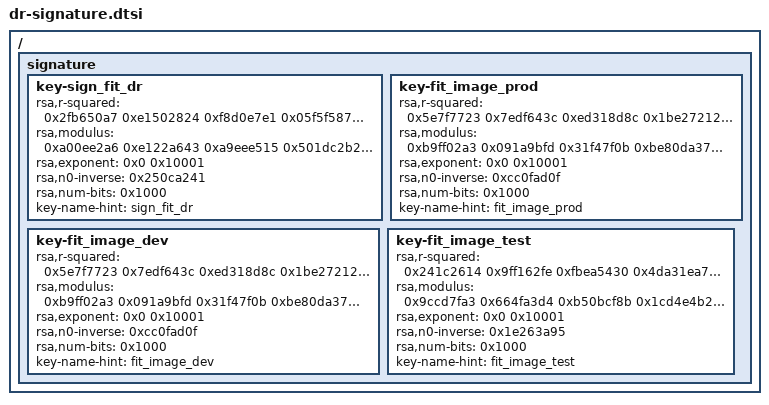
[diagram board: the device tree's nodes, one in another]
/ {
	signature {

		key-sign_fit_dr {
			rsa,r-squared = <
				0x2fb650a7 0xe1502824 0xf8d0e7e1 0x05f5f587
				0xeb7a8b7b 0x9eb11322 0xbd7e9bcb 0x8206080f
				0x1e3cef59 0xcbdcf8fe 0x8d390c50 0x8037e907
				0x23c142a7 0x543cceb7 0x621bd0e6 0x40295e5f
				0x391752dc 0x218a99db 0xe4e37117 0x1306a107
				0x48409d4e 0xf80b34be 0x4c174da6 0x78f461b9
				0xd5cb24da 0x44b6b164 0x1b209ac6 0xd7333065
				0xe70ed5af 0x31e8fc6b 0x88b9d6f3 0x11a98321
				0x17a40d6b 0xe5fcba2b 0x6326f2e3 0x79c96d24
				0x60183420 0xe6ca6753 0x1314e6e8 0xf78f9bad
				0xf9584ec3 0x8d96b01a 0xd9dd74f8 0xb382ae35
				0x01f6a1ef 0xf0c2f379 0x0aa90f7c 0xfae0b0cb
				0x009eaa74 0xa32082ee 0xbd0abb01 0x92b7ecca
				0xcaa34dc5 0xc3ba530f 0x292755a8 0x004a4f96
				0x81c959b3 0x697cb131 0xfade8068 0xeed65604
				0xcbabe22d 0x4c5c093d 0xfacc3274 0x638f702e
				0x1f32caa0 0x23070771 0xaa4fb380 0x864e15f1
				0x963bd9d5 0x59dc21a5 0xd2d697c0 0xe0d09aed
				0x384b783b 0x9a5ba691 0x451a8d71 0x527e2852
				0x044bebe8 0x35c86a40 0x13f5a72b 0x7377f698
				0xefaf8fc3 0x18c6d440 0x7d257bfa 0xb29f66de
				0xa95f6079 0x5b55c139 0x1c2a168a 0x553f8544
				0x6c0fc641 0x30a914b1 0xc3c75446 0x1aaf9767
				0x19353101 0xdaf74e9b 0xab11b880 0x2d505a41
				0xe6ab1942 0xdb8592e8 0xea2b1317 0xdabceab7
				0x2d5bd5dc 0x5b2d1a1b 0x47bb324f 0x76ce07c4
				0xb0584434 0xcea93d41 0xb47369fc 0x6bda6210
				0x47a1fa15 0x17a2eaad 0x804510fd 0x710039de
				0x123fba1a 0xc02a9ba6 0xc5431eba 0xa96c2a70
				0x09beacbe 0x89b1bf60 0x5a650585 0x33fd26ca
				0x9bf031a4 0x23501331 0x43520b8d 0x8d8d7ec7
				0x51b2d9a4 0x05c2f2e8 0x9d800997 0xadcf95dd>;
			rsa,modulus= <
				0xa00ee2a6 0xe122a643 0xa9eee515 0x501dc2b2
				0x8f87f49b 0x566f039c 0x6ca342ff 0xdfe728c8
				0x5d0c82f9 0xaa106b88 0xc51a33b4 0x5aea1a0b
				0xf780bc2f 0xf09a7ae7 0xdb86575c 0x652f8f2b
				0x6c101755 0x1bb0c52b 0x005ab815 0x106d1b86
				0xd66664f4 0x87d39dac 0x89ed97ae 0xfb83fa53
				0x511d619e 0x1c3f01d5 0x858c266b 0xd2375fa9
				0x09c2f104 0x677b7182 0x45ddfc13 0x7c301188
				0x5ef2b94a 0x991a366b 0x1047d3fb 0x90499069
				0x3e91c15e 0x0897c597 0x30933df0 0x60fe302b
				0xaf395dca 0xbe724033 0x81157f75 0x707f5711
				0x793b7b2a 0x20abeba5 0x80fe7464 0x017028ac
				0x15a0745b 0x699a4220 0xbab8455d 0x136c8bbc
				0xbb8e1f8e 0xa4ffa878 0x1f366be0 0x80975e46
				0x67200689 0x503ef476 0x0be48772 0xce8e77ba
				0x4fd15916 0x884b39ea 0x1b784e04 0x8254f573
				0x42288801 0x393ba201 0xe6aaede2 0xcf62348b
				0x6bf3d6dd 0xeda56748 0x0d336017 0x80448b4e
				0x1e83f05c 0x7484a4d9 0x5f9dda54 0x0742f0f3
				0xedd00d16 0x9d09a67d 0x0f41d03b 0x9a09c160
				0xe2c45df0 0x5cb8b441 0x7d954e50 0x744d3a75
				0x7eae8f1a 0x4ce7b501 0x519b1e55 0x666fbfaf
				0x81e31ba1 0x0a7757bf 0x7b38c350 0x459175c4
				0x4848fef4 0x372e631c 0x0d922ae3 0x987b57be
				0x1a81a596 0x7a16dbae 0x52f839f8 0x3696d8eb
				0xd8810d9f 0x4d36db32 0x2be18174 0x5087b886
				0xc74ab6ad 0x2fe797cd 0x4f760b48 0x7653d92a
				0x3c50c45c 0x4b5921ce 0xef45d786 0x6fa53475
				0x3adaef9f 0x226e0f40 0x36fe1c5d 0xe47e021b
				0x826a2ba3 0xa2e30394 0x6c58b319 0x1002f051
				0x62a1a22a 0x29d97516 0x2af0ab82 0x06fe8223
				0xa7e085f5 0x76b9f9dc 0x9b242b3c 0x709b923f>;
			rsa,exponent = <0x0 0x10001>;
			rsa,n0-inverse = <0x250ca241>;
			rsa,num-bits = <0x1000>;
			key-name-hint = "sign_fit_dr";
		};

		key-fit_image_prod {
			rsa,r-squared = <
				0x5e7f7723 0x7edf643c 0xed318d8c 0x1be27212
				0x87641605 0x99bf037b 0xbbb2278b 0x48a3ab02
				0xbbbebda8 0xbc994abd 0x35f1f0e1 0xeb78b2e1
				0xfd072532 0x99a55eac 0x50be9aef 0xf11b851c
				0x0294a416 0x81ec1588 0xcace2984 0xd508afe3
				0x8f89d704 0x1e74e7df 0x12f9cd6f 0x2916cb16
				0xb9531ba1 0x9f27f594 0x2e4b36fa 0xba67bce0
				0x696ca8a9 0x73f5885e 0x1542c50e 0x50430568
				0xead3d1c3 0x1589bff5 0xbf9a94a7 0xf0a8f86a
				0x1e82deb6 0xc0ba71f3 0x7791eac0 0x8c42e734
				0xdd7285b3 0x9666fe51 0x926850e5 0x3ea37424
				0x72ebab59 0x7e66f9c1 0x23f030b6 0x70c079f7
				0x74a72549 0x16230ba9 0x8d69cf98 0x191c7c44
				0xb28715f7 0x580bb377 0x977fabcc 0xf6d44408
				0x5194f852 0x2cc58ab9 0xda395064 0x7ce8d213
				0xe7931e51 0x5a73dd68 0xdbb619c6 0x31709c8b
				0x176126ee 0x408469a8 0x27d16301 0x36d61dfc
				0x5e16a862 0x26cb8019 0x3f2204d9 0x13726397
				0x670e83ba 0x29c6a6eb 0x9c0d1436 0x235adec0
				0x365875ad 0xc5e6d473 0x02e92297 0x2833cda9
				0x3efea6c0 0x8b06fd7c 0x9d2e4e84 0xe64ee466
				0x735e2984 0x89090d3c 0x271bcf65 0x7ab1a58e
				0x96899b34 0x9a15d437 0x590b8b47 0xfc0d41fb
				0x889bcf9e 0x9fb11dad 0x61c32e2c 0x55126e7e
				0x492ff152 0xe74437f9 0x830685d3 0x037e5f31
				0x985a7a69 0x228de426 0x47720340 0x55697744
				0x90a6e2d7 0x65169746 0xa3e04e9c 0x6a592eb2
				0xa5c03426 0xec1f1dff 0x3dc86537 0xeb32b971
				0x73939bfa 0x1c45b14e 0x3bd2e8ca 0x3b48d638
				0xb11e65b3 0xa2716628 0x0019a273 0xb74ed9d2
				0xaec9f007 0xfe2ac7ce 0x6f25dda9 0xd989fe5d
				0x7b339440 0xaaccbd71 0xfe5bbbf6 0x21ca9f7d>;
			rsa,modulus= <
				0xb9ff02a3 0x091a9bfd 0x31f47f0b 0xbe80da37
				0x8c33ba51 0x2ff67e8c 0x239575d3 0x855c9eb2
				0x6b491d9f 0xabf75f1e 0xd673483b 0xfe334de7
				0x2aecd022 0x41c0fc0a 0xb0bc0587 0xe2b6349e
				0xbba1a138 0xedddb33b 0x186843bf 0x6b3ea699
				0x4ea4dcff 0x0d01ee09 0x112a2dd3 0xac1644b7
				0xf9f9cdd6 0x8bf863fc 0x5b4e659c 0x53f2162c
				0x03713f88 0xedfbdd0b 0x08e72807 0xfd57155f
				0x6b7209bd 0xbe439fd3 0xbf2babb3 0xf440853d
				0x867e56a0 0xa8d2d967 0xe1327a2b 0x4b0705b3
				0x29179650 0x4d5aa9a8 0x845197dc 0xbaabfa41
				0xcac85cc7 0xaedf064f 0xa8942873 0xad766abb
				0xcc659b0c 0x165eaae0 0x735aa0a3 0x5f799797
				0x6b12220b 0xeeb018c1 0x45055bb7 0xdd7462a4
				0xa765db3b 0x62a1aae4 0x00ba9644 0xae22f488
				0x8dd9d7dc 0x6e80d659 0xe49aedbe 0xfd0212ee
				0xc8180670 0x92494b84 0xab32ef8b 0xf3ed4fb3
				0x9f8dcca1 0x6d243497 0x11ec86e6 0x8dc485bc
				0x547ca485 0x4a20f1f6 0xf490293d 0x81aaf7a7
				0x53e3bdde 0x9c10512d 0x4693e06f 0xf4010d2a
				0x653673d2 0x2dc81307 0xddfa74cd 0xd2961507
				0x185e46ae 0x8013a7c4 0x05d32901 0x3fea3830
				0x3d53df45 0x34ca7f86 0x8c0e7df9 0xf6fedcdb
				0x6added1b 0x19469564 0x17dee6d7 0xdf5452aa
				0x9ee1d94c 0xd841d243 0x47ef1ba1 0x6f1b3de8
				0x9743f339 0xd69b5fb4 0x2d174d61 0x8563c3d4
				0x8dcfeb48 0xe1dc7d36 0x3dcb375b 0xd1c64400
				0x2978c848 0x9c9d5cbb 0x7b6a0a89 0x841db821
				0x00aa21e5 0xbc67d65b 0x4796f8cd 0xde5ef50f
				0x5f91df16 0x7732798b 0x2037862d 0x1b761d33
				0x4d6196ac 0x85039649 0xe3677af2 0x9faa8116
				0xdf398e1d 0x841e10cc 0xc53b906c 0x4bf65e11>;
			rsa,exponent = <0x0 0x10001>;
			rsa,n0-inverse = <0xcc0fad0f>;
			rsa,num-bits = <0x1000>;
			key-name-hint = "fit_image_prod";
		};

		key-fit_image_dev {
			rsa,r-squared = <
				0x5e7f7723 0x7edf643c 0xed318d8c 0x1be27212
				0x87641605 0x99bf037b 0xbbb2278b 0x48a3ab02
				0xbbbebda8 0xbc994abd 0x35f1f0e1 0xeb78b2e1
				0xfd072532 0x99a55eac 0x50be9aef 0xf11b851c
				0x0294a416 0x81ec1588 0xcace2984 0xd508afe3
				0x8f89d704 0x1e74e7df 0x12f9cd6f 0x2916cb16
				0xb9531ba1 0x9f27f594 0x2e4b36fa 0xba67bce0
				0x696ca8a9 0x73f5885e 0x1542c50e 0x50430568
				0xead3d1c3 0x1589bff5 0xbf9a94a7 0xf0a8f86a
				0x1e82deb6 0xc0ba71f3 0x7791eac0 0x8c42e734
				0xdd7285b3 0x9666fe51 0x926850e5 0x3ea37424
				0x72ebab59 0x7e66f9c1 0x23f030b6 0x70c079f7
				0x74a72549 0x16230ba9 0x8d69cf98 0x191c7c44
				0xb28715f7 0x580bb377 0x977fabcc 0xf6d44408
				0x5194f852 0x2cc58ab9 0xda395064 0x7ce8d213
				0xe7931e51 0x5a73dd68 0xdbb619c6 0x31709c8b
				0x176126ee 0x408469a8 0x27d16301 0x36d61dfc
				0x5e16a862 0x26cb8019 0x3f2204d9 0x13726397
				0x670e83ba 0x29c6a6eb 0x9c0d1436 0x235adec0
				0x365875ad 0xc5e6d473 0x02e92297 0x2833cda9
				0x3efea6c0 0x8b06fd7c 0x9d2e4e84 0xe64ee466
				0x735e2984 0x89090d3c 0x271bcf65 0x7ab1a58e
				0x96899b34 0x9a15d437 0x590b8b47 0xfc0d41fb
				0x889bcf9e 0x9fb11dad 0x61c32e2c 0x55126e7e
				0x492ff152 0xe74437f9 0x830685d3 0x037e5f31
				0x985a7a69 0x228de426 0x47720340 0x55697744
				0x90a6e2d7 0x65169746 0xa3e04e9c 0x6a592eb2
				0xa5c03426 0xec1f1dff 0x3dc86537 0xeb32b971
				0x73939bfa 0x1c45b14e 0x3bd2e8ca 0x3b48d638
				0xb11e65b3 0xa2716628 0x0019a273 0xb74ed9d2
				0xaec9f007 0xfe2ac7ce 0x6f25dda9 0xd989fe5d
				0x7b339440 0xaaccbd71 0xfe5bbbf6 0x21ca9f7d>;
			rsa,modulus= <
				0xb9ff02a3 0x091a9bfd 0x31f47f0b 0xbe80da37
				0x8c33ba51 0x2ff67e8c 0x239575d3 0x855c9eb2
				0x6b491d9f 0xabf75f1e 0xd673483b 0xfe334de7
				0x2aecd022 0x41c0fc0a 0xb0bc0587 0xe2b6349e
				0xbba1a138 0xedddb33b 0x186843bf 0x6b3ea699
				0x4ea4dcff 0x0d01ee09 0x112a2dd3 0xac1644b7
				0xf9f9cdd6 0x8bf863fc 0x5b4e659c 0x53f2162c
				0x03713f88 0xedfbdd0b 0x08e72807 0xfd57155f
				0x6b7209bd 0xbe439fd3 0xbf2babb3 0xf440853d
				0x867e56a0 0xa8d2d967 0xe1327a2b 0x4b0705b3
				0x29179650 0x4d5aa9a8 0x845197dc 0xbaabfa41
				0xcac85cc7 0xaedf064f 0xa8942873 0xad766abb
				0xcc659b0c 0x165eaae0 0x735aa0a3 0x5f799797
				0x6b12220b 0xeeb018c1 0x45055bb7 0xdd7462a4
				0xa765db3b 0x62a1aae4 0x00ba9644 0xae22f488
				0x8dd9d7dc 0x6e80d659 0xe49aedbe 0xfd0212ee
				0xc8180670 0x92494b84 0xab32ef8b 0xf3ed4fb3
				0x9f8dcca1 0x6d243497 0x11ec86e6 0x8dc485bc
				0x547ca485 0x4a20f1f6 0xf490293d 0x81aaf7a7
				0x53e3bdde 0x9c10512d 0x4693e06f 0xf4010d2a
				0x653673d2 0x2dc81307 0xddfa74cd 0xd2961507
				0x185e46ae 0x8013a7c4 0x05d32901 0x3fea3830
				0x3d53df45 0x34ca7f86 0x8c0e7df9 0xf6fedcdb
				0x6added1b 0x19469564 0x17dee6d7 0xdf5452aa
				0x9ee1d94c 0xd841d243 0x47ef1ba1 0x6f1b3de8
				0x9743f339 0xd69b5fb4 0x2d174d61 0x8563c3d4
				0x8dcfeb48 0xe1dc7d36 0x3dcb375b 0xd1c64400
				0x2978c848 0x9c9d5cbb 0x7b6a0a89 0x841db821
				0x00aa21e5 0xbc67d65b 0x4796f8cd 0xde5ef50f
				0x5f91df16 0x7732798b 0x2037862d 0x1b761d33
				0x4d6196ac 0x85039649 0xe3677af2 0x9faa8116
				0xdf398e1d 0x841e10cc 0xc53b906c 0x4bf65e11>;
			rsa,exponent = <0x0 0x10001>;
			rsa,n0-inverse = <0xcc0fad0f>;
			rsa,num-bits = <0x1000>;
			key-name-hint = "fit_image_dev";
		};

		key-fit_image_test {
			rsa,r-squared = <
				0x241c2614 0x9ff162fe 0xfbea5430 0x4da31ea7
				0x43a1c562 0x5ffeb33b 0xb7093ce2 0xa87a453a
				0x59547fd8 0x515b963d 0x822a03c6 0x5427114d
				0xa55c44a5 0xf949deb5 0x773a2fbe 0x3d491354
				0x0cd54bea 0x6fa9b8d6 0xe86239a7 0x852847b9
				0x193dc6ca 0x7e1ddd3e 0x631d5b9d 0xdbd9aa97
				0x98e7f553 0x1a67fcd8 0xdc216a92 0x7900568d
				0x6c38cb61 0x1d4297e7 0xa0252e5c 0xfaefcdb6
				0xfd54e012 0x82b550ad 0x5570d87e 0xaa2d6434
				0x2971db4d 0x5e4f45c1 0xd04b31ed 0x0732e318
				0x012f36f2 0x54e2b6ee 0x823ab9c6 0x388b7d10
				0xa6064b4e 0x787c403c 0x0542e999 0x6b1b1a39
				0x2bf3ff5b 0xc0b5db9c 0xae1c44c9 0xf58f39cc
				0x06c8177a 0xedf713d4 0xe65fa148 0xd8d0cb6c
				0xb819883e 0x50aaea1c 0x6d3f7a0c 0x201ddb6e
				0x63c99d46 0x4970e412 0x3cb5d9c4 0xbdc5140b
				0x234bd072 0x6a7b9111 0x960094aa 0xfd940c6c
				0x45072568 0xcc8c86fa 0x0f0e81f0 0xa1b1d3cf
				0x5ac842f3 0xfef38329 0xb07d6d84 0xdd1c59da
				0x9223f2d3 0x3c395449 0x203dac73 0xb26d9b48
				0xdea5b7f1 0xd43ae70f 0xd08746c1 0x0c757430
				0x34c16a27 0x19bac346 0x71682748 0x6efc82c7
				0xeb232bee 0xa0207f4e 0xbb376ae0 0x96406eef
				0x3b04455d 0xff1f2796 0xdca03c0c 0x34daf608
				0x0f92510e 0x97abc028 0x351b0f0a 0x16a37d0a
				0x78a0b27d 0x75fa8cae 0xd82a40d7 0xdd7d7853
				0x0d75fbea 0x2bb1a1c9 0xf3a40a75 0x876412a6
				0xabda9894 0xe73ad910 0xc104cb19 0x274452bd
				0xd6caa936 0x43b96a69 0x911d55df 0x9fcdf453
				0x87620096 0x7fbd16d1 0x4fae4294 0xcb09699c
				0xba8050f0 0x6f45079f 0xeae65541 0xfa19f6f0
				0x876f2e6e 0xda42db3b 0xb661bcc5 0x039166ca>;
			rsa,modulus= <
				0x9ccd7fa3 0x664fa3d4 0xb50bcf8b 0x1cd4e4b2
				0xc087440b 0x677f5779 0x88ba7493 0xce1c842b
				0x76ca0022 0x03514f20 0x61f5952c 0x0f006d4c
				0x349c5020 0x8a7e11c2 0xf61dd4a5 0xfec65e74
				0x25ffc9fb 0x0f52b06e 0x88932f98 0x183dd311
				0x471676eb 0x74269f7c 0x3a02a4e5 0x5fe4c7a8
				0xc6aaaefa 0xdd85b1fb 0x6283e592 0x4348dc61
				0x12337ac7 0x94e88ff6 0xbef3a8fb 0x6c6fc0cf
				0x8ac30fa7 0x97a06569 0xe2d8572a 0x1b6a4f74
				0x1628e507 0xfe6d34d7 0x610f7939 0xeccddadd
				0xa82b798e 0x6f5c8779 0x2b044cb9 0x10a7c84a
				0x948e48ea 0x6d0126db 0xca113206 0xe018d817
				0x6f91d1c5 0x14354864 0x5747b522 0x4a3553a8
				0x20f6352b 0x25f458d6 0xcf1ab734 0xe35839f9
				0xc3d46273 0xc9e11f45 0xee9f4e67 0xa25ca99d
				0x975f9c3f 0xb43fedfa 0x21d5fe0c 0xdb8c5c41
				0xf9c26712 0x5df2cc46 0xabad265e 0xbe7545c2
				0x0b61ae9c 0xf6140144 0x5ab06a78 0x9ee48cdd
				0xf98a3303 0x102e11ce 0xb681e2ee 0x69bac98d
				0x3d200d96 0xd02de90d 0xba099e7c 0x2c6d528d
				0xdeb002b5 0xe15af145 0xe347345e 0xbe398fb9
				0xf78e45f4 0x5dd7a70f 0xeaf9bd25 0x7dda314e
				0x2bc7a562 0x370d69a0 0x032de04d 0x9fc38140
				0x06dd201b 0x6a4c669d 0x7e85224a 0x3d290dee
				0xf1ca5c2a 0x8e6c6dc6 0x2614d501 0x0bf45077
				0x6e12031c 0x5bf895e2 0xf5fcff89 0xabd96ca8
				0x66b5da40 0xdbf4a0d1 0xfa7bf6aa 0xa8ee3d90
				0xec0a3de1 0xe12a8753 0xf17d291e 0x7d8197a1
				0x725dcaec 0xb0af5c08 0x8cf23d6b 0x72bc9ca1
				0x2ab70b62 0xa7405a4e 0xbe087b11 0x21660ee5
				0x73adf118 0xff5ad92f 0x936edc52 0x0a4fd649
				0xca9613f3 0xae664fc4 0x029d3e9c 0x94443f43>;
			rsa,exponent = <0x0 0x10001>;
			rsa,n0-inverse = <0x1e263a95>;
			rsa,num-bits = <0x1000>;
			key-name-hint = "fit_image_test";
		};

	};
};
